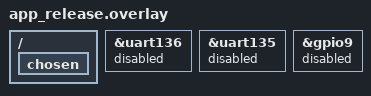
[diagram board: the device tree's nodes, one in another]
/*
 * Copyright (c) 2023 Nordic Semiconductor ASA
 *
 * SPDX-License-Identifier: LicenseRef-Nordic-5-Clause
 */

 #include "app.overlay"

 / {
	chosen {
		 /delete-property/ zephyr,console;
	};
 };
 
&uart136 {
	status = "disabled";
};

&uart135 {
	status = "disabled";
};

&gpio9 {
	status = "disabled";
};
